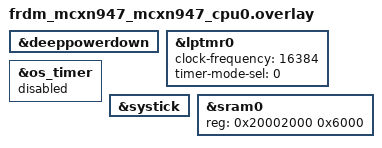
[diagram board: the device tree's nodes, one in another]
/*
 * SPDX-FileCopyrightText: Copyright 2026 NXP
 *
 * SPDX-License-Identifier: Apache-2.0
 */

/* Suspend-to-RAM (Deep Power Down) is opt-in: the SoC disables it by default.
 * This sample places its working set in retained RAM and arms a wakeup source,
 * so enable the state here.
 */
&deeppowerdown {
	status = "okay";
};

&lptmr0 {
	status = "okay";
	clock-frequency = <16384>;
	timer-mode-sel = <0>;
};

&os_timer {
	status = "disabled";
};

&systick {
	status = "okay";
};

/* Constrain zephyr,sram to RAMA1-RAMA3 (24 KB at 0x20002000) so the whole
 * retained working set is both kept across Deep Power Down and kept clear of
 * the boot ROM scratch.
 */
&sram0 {
	reg = <0x20002000 0x6000>;
};
